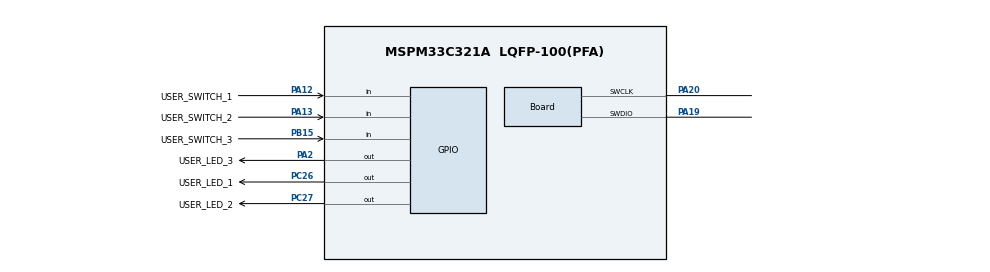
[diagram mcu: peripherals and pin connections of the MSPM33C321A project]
//@cliArgs --device "MSPM33C321A" --package "LQFP-100(PFA)" --part "Default"
//@v2CliArgs --device "MSPM33C321A" --package "LQFP-100(PFA)"
// @cliArgs --board /ti/boards/LP_MSPM33C321A --rtos nortos


/**
 * Import the modules used in this configuration.
 */
const GPIO   = scripting.addModule("/ti/driverlib/GPIO", {}, false);
const GPIO1  = GPIO.addInstance();
const GPIO2  = GPIO.addInstance();
const SYSCTL = scripting.addModule("/ti/driverlib/SYSCTL");


/**
 * Write custom configuration values to the imported modules.
 */
GPIO1.$name                               = "GPIO_LEDS";
GPIO1.associatedPins.create(3);
GPIO1.associatedPins[0].$name             = "USER_LED_1";
GPIO1.associatedPins[0].launchPadShortcut = "LED2RedEn";
GPIO1.associatedPins[0].pin.$assign       = "PC26";
GPIO1.associatedPins[1].$name             = "USER_LED_2";
GPIO1.associatedPins[1].launchPadShortcut = "LED2GreenEn";
GPIO1.associatedPins[1].pin.$assign       = "PC27";
GPIO1.associatedPins[2].$name             = "USER_LED_3";
GPIO1.associatedPins[2].launchPadShortcut = "LED2BlueEn";
GPIO1.associatedPins[2].pin.$assign       = "PA2";

const Board                       = scripting.addModule("/ti/driverlib/Board", {}, false);
Board.peripheral.$assign          = "DEBUGSS";
Board.peripheral.swclkPin.$assign = "PA20";
Board.peripheral.swdioPin.$assign = "PA19";

GPIO2.$name                                 = "GPIO_SWITCHES";
GPIO2.associatedPins.create(3);
GPIO2.associatedPins[0].$name               = "USER_SWITCH_1";
GPIO2.associatedPins[0].assignedPortSegment = "Lower";
GPIO2.associatedPins[0].assignedPort        = "PORTA";
GPIO2.associatedPins[0].assignedPin         = "12";
GPIO2.associatedPins[0].direction           = "INPUT";
GPIO2.associatedPins[0].interruptEn         = true;
GPIO2.associatedPins[0].polarity            = "RISE";
GPIO2.associatedPins[0].pin.$assign         = "PA12";
GPIO2.associatedPins[1].$name               = "USER_SWITCH_2";
GPIO2.associatedPins[1].direction           = "INPUT";
GPIO2.associatedPins[1].assignedPort        = "PORTA";
GPIO2.associatedPins[1].assignedPortSegment = "Lower";
GPIO2.associatedPins[1].assignedPin         = "13";
GPIO2.associatedPins[1].interruptEn         = true;
GPIO2.associatedPins[1].polarity            = "RISE";
GPIO2.associatedPins[1].pin.$assign         = "PA13";
GPIO2.associatedPins[2].$name               = "USER_SWITCH_3";
GPIO2.associatedPins[2].direction           = "INPUT";
GPIO2.associatedPins[2].assignedPort        = "PORTB";
GPIO2.associatedPins[2].assignedPortSegment = "Lower";
GPIO2.associatedPins[2].assignedPin         = "15";
GPIO2.associatedPins[2].interruptEn         = true;
GPIO2.associatedPins[2].polarity            = "RISE";
GPIO2.associatedPins[2].pin.$assign         = "PB15";

SYSCTL.forceDefaultClkConfig = true;
SYSCTL.peripheral.$assign    = "SYSCTL";

const ProjectConfig              = scripting.addModule("/ti/project_config/ProjectConfig", {}, false);
ProjectConfig.migrationCondition = true;

ProjectConfig.genLinker  = true;
ProjectConfig.genStartup = true;
ProjectConfig.genOpts    = true;
ProjectConfig.genLibs    = true;
